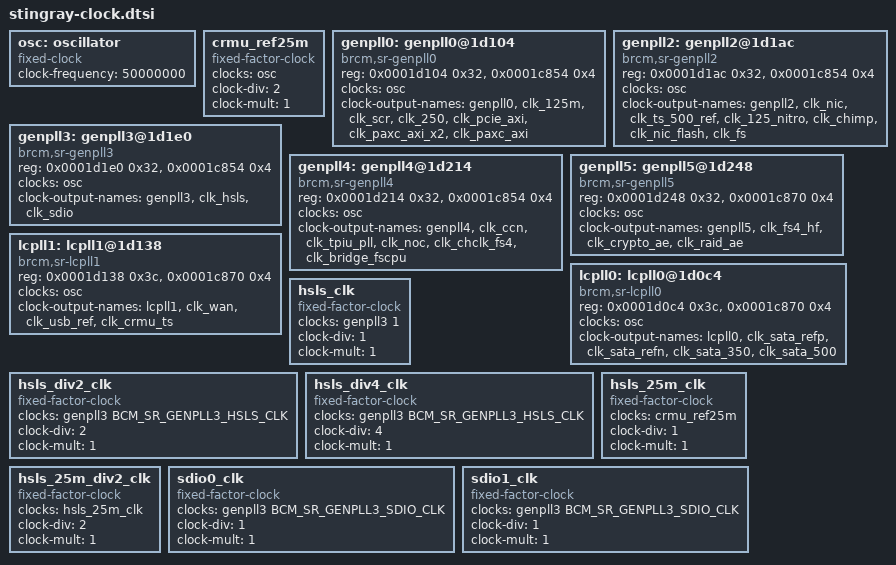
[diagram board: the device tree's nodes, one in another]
#include <dt-bindings/clock/bcm-sr.h>
		osc: oscillator {
			#clock-cells = <0>;
			compatible = "fixed-clock";
			clock-frequency = <50000000>;
		};
		crmu_ref25m: crmu_ref25m {
			#clock-cells = <0>;
			compatible = "fixed-factor-clock";
			clocks = <&osc>;
			clock-div = <2>;
			clock-mult = <1>;
		};
		genpll0: genpll0@1d104 {
			#clock-cells = <1>;
			compatible = "brcm,sr-genpll0";
			reg = <0x0001d104 0x32>,
			      <0x0001c854 0x4>;
			clocks = <&osc>;
			clock-output-names = "genpll0", "clk_125m", "clk_scr",
					     "clk_250", "clk_pcie_axi",
					     "clk_paxc_axi_x2",
					     "clk_paxc_axi";
		};
		genpll2: genpll2@1d1ac {
			#clock-cells = <1>;
			compatible = "brcm,sr-genpll2";
			reg = <0x0001d1ac 0x32>,
			      <0x0001c854 0x4>;
			clocks = <&osc>;
			clock-output-names = "genpll2", "clk_nic",
					     "clk_ts_500_ref", "clk_125_nitro",
					     "clk_chimp", "clk_nic_flash",
					     "clk_fs";
		};
		genpll3: genpll3@1d1e0 {
			#clock-cells = <1>;
			compatible = "brcm,sr-genpll3";
			reg = <0x0001d1e0 0x32>,
			      <0x0001c854 0x4>;
			clocks = <&osc>;
			clock-output-names = "genpll3", "clk_hsls",
					     "clk_sdio";
		};
		genpll4: genpll4@1d214 {
			#clock-cells = <1>;
			compatible = "brcm,sr-genpll4";
			reg = <0x0001d214 0x32>,
			      <0x0001c854 0x4>;
			clocks = <&osc>;
			clock-output-names = "genpll4", "clk_ccn",
					     "clk_tpiu_pll", "clk_noc",
					     "clk_chclk_fs4",
					     "clk_bridge_fscpu";
		};
		genpll5: genpll5@1d248 {
			#clock-cells = <1>;
			compatible = "brcm,sr-genpll5";
			reg = <0x0001d248 0x32>,
			      <0x0001c870 0x4>;
			clocks = <&osc>;
			clock-output-names = "genpll5", "clk_fs4_hf",
					     "clk_crypto_ae", "clk_raid_ae";
		};
		lcpll0: lcpll0@1d0c4 {
			#clock-cells = <1>;
			compatible = "brcm,sr-lcpll0";
			reg = <0x0001d0c4 0x3c>,
			      <0x0001c870 0x4>;
			clocks = <&osc>;
			clock-output-names = "lcpll0", "clk_sata_refp",
					     "clk_sata_refn", "clk_sata_350",
					     "clk_sata_500";
		};
		lcpll1: lcpll1@1d138 {
			#clock-cells = <1>;
			compatible = "brcm,sr-lcpll1";
			reg = <0x0001d138 0x3c>,
			      <0x0001c870 0x4>;
			clocks = <&osc>;
			clock-output-names = "lcpll1", "clk_wan",
					     "clk_usb_ref",
					     "clk_crmu_ts";
		};
		hsls_clk: hsls_clk {
			#clock-cells = <0>;
			compatible = "fixed-factor-clock";
			clocks = <&genpll3 1>;
			clock-div = <1>;
			clock-mult = <1>;
		};
		hsls_div2_clk: hsls_div2_clk {
			#clock-cells = <0>;
			compatible = "fixed-factor-clock";
			clocks = <&genpll3 BCM_SR_GENPLL3_HSLS_CLK>;
			clock-div = <2>;
			clock-mult = <1>;
		};
		hsls_div4_clk: hsls_div4_clk {
			#clock-cells = <0>;
			compatible = "fixed-factor-clock";
			clocks = <&genpll3 BCM_SR_GENPLL3_HSLS_CLK>;
			clock-div = <4>;
			clock-mult = <1>;
		};
		hsls_25m_clk: hsls_25m_clk {
			#clock-cells = <0>;
			compatible = "fixed-factor-clock";
			clocks = <&crmu_ref25m>;
			clock-div = <1>;
			clock-mult = <1>;
		};
		hsls_25m_div2_clk: hsls_25m_div2_clk {
			#clock-cells = <0>;
			compatible = "fixed-factor-clock";
			clocks = <&hsls_25m_clk>;
			clock-div = <2>;
			clock-mult = <1>;
		};
		sdio0_clk: sdio0_clk {
			#clock-cells = <0>;
			compatible = "fixed-factor-clock";
			clocks = <&genpll3 BCM_SR_GENPLL3_SDIO_CLK>;
			clock-div = <1>;
			clock-mult = <1>;
		};
		sdio1_clk: sdio1_clk {
			#clock-cells = <0>;
			compatible = "fixed-factor-clock";
			clocks = <&genpll3 BCM_SR_GENPLL3_SDIO_CLK>;
			clock-div = <1>;
			clock-mult = <1>;
		};
